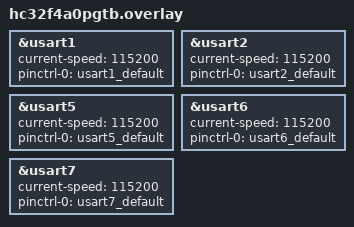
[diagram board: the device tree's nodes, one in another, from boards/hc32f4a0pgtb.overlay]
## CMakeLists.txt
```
# SPDX-License-Identifier: Apache-2.0

cmake_minimum_required(VERSION 3.20.0)

# Point Zephyr at the hc32f/ out-of-tree SoC + board tree (sibling directory).
set(HC32F_ROOT ${CMAKE_CURRENT_SOURCE_DIR}/../hc32f)
list(APPEND SOC_ROOT   ${HC32F_ROOT})
list(APPEND BOARD_ROOT ${HC32F_ROOT})
list(APPEND DTS_ROOT   ${HC32F_ROOT})

find_package(Zephyr REQUIRED HINTS $ENV{ZEPHYR_BASE})
project(fmr_cc)

target_include_directories(app PRIVATE src)

target_sources(app PRIVATE
	src/main.c
	src/app_msg.c
	src/crc16_modbus.c
	src/doraemon_pack.c
	src/led_statu.c
	src/wbus.c
	src/imu5115.c
	src/moto.c
	src/servo.c
	src/comm_485_lift.c
	src/manual_ctrl.c
	src/battery.c
	src/usb_uplink.c
)
```

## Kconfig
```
# SPDX-License-Identifier: Apache-2.0

mainmenu "FMR_CC application"

source "Kconfig.zephyr"

menu "FMR_CC business modules"

config APP_FMR_WBUS
	bool "WBUS/SBUS receiver (USART2)"
	default y

config APP_FMR_IMU
	bool "IMU-5115 parser (USART1)"
	default y

config APP_FMR_MOTO
	bool "Motor Modbus RTU (USART6 + RS485)"
	default y

config APP_FMR_SERVO
	bool "Feetech servo (USART7 + RS485)"
	default y

config APP_FMR_LIFT
	bool "Lift Modbus RTU (USART5 + RS485)"
	default y

config APP_FMR_MANUAL_CTRL
	bool "Manual control (WBUS->motor/servo/lift mapping)"
	default y

config APP_FMR_LED_595
	bool "74HC595 LED status bit-bang"
	default y

config APP_FMR_BATTERY
	bool "Battery ADC sampler"
	default n
	help
	  Requires an ADC driver for HC32F4A0 which is not yet implemented.

config APP_FMR_USB_UPLINK
	bool "USB CDC-ACM uplink"
	default n
	help
	  Requires an HC32F4A0 USB device controller driver which is not
	  yet implemented.  When disabled the uplink falls back to USART3
	  (the debug console).

endmenu
```

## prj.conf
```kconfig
# FMR_CC Zephyr port: base config
CONFIG_MAIN_STACK_SIZE=2048
CONFIG_SYSTEM_WORKQUEUE_STACK_SIZE=2048

CONFIG_GPIO=y
CONFIG_PINCTRL=y
CONFIG_SERIAL=y
CONFIG_UART_INTERRUPT_DRIVEN=y
CONFIG_CONSOLE=y
CONFIG_UART_CONSOLE=y

CONFIG_LOG=y
CONFIG_LOG_MODE_DEFERRED=y
CONFIG_LOG_DEFAULT_LEVEL=3
CONFIG_LOG_BUFFER_SIZE=2048

CONFIG_POLL=y
CONFIG_EVENTS=y
CONFIG_RING_BUFFER=y

# MPU off for bring-up
CONFIG_ARM_MPU=n
CONFIG_HW_STACK_PROTECTION=n
CONFIG_THREAD_NAME=y
CONFIG_THREAD_MONITOR=y

# Business module toggles
CONFIG_APP_FMR_WBUS=y
CONFIG_APP_FMR_IMU=y
CONFIG_APP_FMR_MOTO=y
CONFIG_APP_FMR_SERVO=y
CONFIG_APP_FMR_LIFT=y
CONFIG_APP_FMR_MANUAL_CTRL=y
CONFIG_APP_FMR_LED_595=y
# Battery/USB require ADC/USB drivers not yet ported; compile as stubs.
CONFIG_APP_FMR_BATTERY=n
CONFIG_APP_FMR_USB_UPLINK=n
```

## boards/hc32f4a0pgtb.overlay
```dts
/*
 * SPDX-License-Identifier: Apache-2.0
 *
 * FMR_CC application overlay for hc32f4a0pgtb board.
 * Enables USART1/2/5/6/7 with their pinctrl nodes defined in the board DTS.
 * USART3 is already enabled as the console in the board DTS.
 */

/* IMU5115 - USART1, 115200 8N1 */
&usart1 {
	current-speed = <115200>;
	pinctrl-0 = <&usart1_default>;
	pinctrl-names = "default";
	status = "okay";
};

/*
 * WBUS/SBUS receiver - USART2.
 * Wire protocol: 100000 baud, 8E2, signal-inverted (SBUS standard).
 * TODO: The HC32 UART driver does not yet expose CR1.SBS (start-bit sense
 * inversion), parity or 2-stop-bit DTS properties.  Set 115200 as a
 * placeholder; wbus.c manually patches the USART registers at runtime via
 * sys_write32() until the driver supports these properties.
 */
&usart2 {
	current-speed = <115200>; /* placeholder; wbus.c patches to 100000 + SBS */
	pinctrl-0 = <&usart2_default>;
	pinctrl-names = "default";
	status = "okay";
};

/* Lift RS485 - USART5, 115200 8N1 */
&usart5 {
	current-speed = <115200>;
	pinctrl-0 = <&usart5_default>;
	pinctrl-names = "default";
	status = "okay";
};

/* Motor RS485 - USART6, 115200 8N1 */
&usart6 {
	current-speed = <115200>;
	pinctrl-0 = <&usart6_default>;
	pinctrl-names = "default";
	status = "okay";
};

/* Servo RS485 - USART7, 115200 8N1 */
&usart7 {
	current-speed = <115200>;
	pinctrl-0 = <&usart7_default>;
	pinctrl-names = "default";
	status = "okay";
};
```

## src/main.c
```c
/*
 * SPDX-License-Identifier: Apache-2.0
 *
 * @file main.c
 * @brief FMR_CC main entry point — Zephyr RTOS port.
 *
 * Initialises all modules then returns (Zephyr keeps threads running).
 * Replaces the original bare-metal superloop in main.c.
 *
 * Periodic tasks previously handled by soft_timer.c are now implemented
 * with k_work_delayable inside each module.  The timers started here
 * match the original schedule:
 *   - Motor speed poll  : every 200 ms
 *   - Servo/lift poll   : every 1000 ms
 *   - Status upload     : every 200 ms (in usb_uplink.c)
 *   - IMU upload        : every 50 ms  (in usb_uplink.c)
 *   - Battery ADC       : every 10 s   (battery.c TODO)
 */

#include "app_msg.h"
#include "led_statu.h"
#include "wbus.h"
#include "imu5115.h"
#include "moto.h"
#include "servo.h"
#include "comm_485_lift.h"
#include "manual_ctrl.h"
#include "battery.h"
#include "usb_uplink.h"

#include <zephyr/kernel.h>
#include <zephyr/logging/log.h>

LOG_MODULE_REGISTER(main, LOG_LEVEL_INF);

/* Periodic work items for timed polling commands */
static struct k_work_delayable read_speed_work;
static struct k_work_delayable read_servo_lift_work;

static void read_speed_work_fn(struct k_work *w)
{
	moto_cmd_get_all_speed();
	k_work_reschedule((struct k_work_delayable *)w, K_MSEC(200));
}

static void read_servo_lift_work_fn(struct k_work *w)
{
	servo_cmd_get_all_pos();
	comm_485_1_cmd_get_lift_pos();
	k_work_reschedule((struct k_work_delayable *)w, K_MSEC(1000));
}

int main(void)
{
	printk("\n");
	printk("========================================\n");
	printk("  FMR_CC Zephyr Port — starting up      \n");
	printk("  Build: %s %s                           \n", __DATE__, __TIME__);
	printk("========================================\n");

	LOG_INF("Initialising modules...");

	/* Message bus first — everything else uses it */
	app_msg_init();

	/* LED status (optional) */
	if (led_statu_init() != 0) {
		LOG_WRN("led_statu init failed (non-fatal)");
	}

	/* RC receiver */
	if (wbus_init() != 0) {
		LOG_WRN("wbus init failed");
	}

	/* IMU */
	if (imu_init() != 0) {
		LOG_WRN("imu init failed");
	}

	/* Motor controller */
	if (moto_init() != 0) {
		LOG_WRN("moto init failed");
	}

	/* Servo controller */
	if (servo_init() != 0) {
		LOG_WRN("servo init failed");
	}

	/* Lift controller */
	if (comm_485_lift_init() != 0) {
		LOG_WRN("comm_485_lift init failed");
	}

	/* Manual control (RC → motor) */
	if (manual_ctrl_init() != 0) {
		LOG_WRN("manual_ctrl init failed");
	}

	/* Battery ADC (stub) */
	if (battery_init() != 0) {
		LOG_WRN("battery init failed");
	}

	/* USB / console uplink */
	if (usb_uplink_init() != 0) {
		LOG_WRN("usb_uplink init failed");
	}

	/* Start periodic polling work items */
	k_work_init_delayable(&read_speed_work, read_speed_work_fn);
	k_work_reschedule(&read_speed_work, K_MSEC(500)); /* initial delay */

	k_work_init_delayable(&read_servo_lift_work, read_servo_lift_work_fn);
	k_work_reschedule(&read_servo_lift_work, K_MSEC(1000));

	LOG_INF("All modules initialised — system running");

	/*
	 * Returning from main() is valid in Zephyr; the kernel continues to
	 * schedule threads.  No superloop needed.
	 */
	return 0;
}
```

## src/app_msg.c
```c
/*
 * SPDX-License-Identifier: Apache-2.0
 *
 * @file app_msg.c
 * @brief Application message bus implementation.
 *
 * Provides a simple publish/subscribe model on top of Zephyr k_msgq.
 * Replaces the bare-metal msg.c circular queue.
 */

#include "app_msg.h"
#include <zephyr/logging/log.h>
#include <string.h>

LOG_MODULE_REGISTER(app_msg, LOG_LEVEL_INF);

struct subscriber {
	struct k_msgq *q;
	uint32_t       type_mask;
};

static struct subscriber subscribers[APP_MSG_MAX_SUBSCRIBERS];
static int sub_count;

int app_msg_init(void)
{
	memset(subscribers, 0, sizeof(subscribers));
	sub_count = 0;
	LOG_INF("app_msg init");
	return 0;
}

int app_msg_subscribe(struct k_msgq *q, uint32_t type_mask)
{
	if (sub_count >= APP_MSG_MAX_SUBSCRIBERS) {
		LOG_ERR("subscriber table full");
		return -ENOMEM;
	}
	subscribers[sub_count].q         = q;
	subscribers[sub_count].type_mask = type_mask;
	sub_count++;
	return 0;
}

void app_msg_publish(const struct app_msg *msg)
{
	uint32_t bit = BIT(msg->type);

	for (int i = 0; i < sub_count; i++) {
		if (subscribers[i].type_mask & bit) {
			/* Non-blocking: drop if queue is full */
			int ret = k_msgq_put(subscribers[i].q, msg, K_NO_WAIT);
			if (ret) {
				LOG_WRN("msg type %d dropped (q full)", msg->type);
			}
		}
	}
}
```

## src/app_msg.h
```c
/*
 * SPDX-License-Identifier: Apache-2.0
 *
 * @file app_msg.h
 * @brief Application-wide inter-module message bus.
 *
 * Replaces the bare-metal msg.c circular queue.  Each module publishes typed
 * messages; subscribers register a k_msgq and receive copies via
 * app_msg_subscribe() / app_msg_publish().
 *
 * Usage:
 *   // Publisher (e.g. wbus.c):
 *   struct app_msg m = { .type = MSG_RC_FRAME, .rc = frame };
 *   app_msg_publish(&m);
 *
 *   // Subscriber (e.g. manual_ctrl.c):
 *   K_MSGQ_DEFINE(my_q, sizeof(struct app_msg), 8, 4);
 *   app_msg_subscribe(&my_q, BIT(MSG_RC_FRAME));
 *   struct app_msg m;
 *   k_msgq_get(&my_q, &m, K_FOREVER);
 */

#ifndef APP_MSG_H
#define APP_MSG_H

#include <stdint.h>
#include <zephyr/kernel.h>

#ifdef __cplusplus
extern "C" {
#endif

/** Message type identifiers */
enum app_msg_type {
	MSG_RC_FRAME = 0,   /**< WBUS/SBUS decoded channel data */
	MSG_IMU_FRAME,      /**< IMU5115 decoded frame */
	MSG_MOTO_STATUS,    /**< Motor speed feedback */
	MSG_SERVO_STATUS,   /**< Servo position feedback */
	MSG_LIFT_STATUS,    /**< Lift position feedback */
	MSG_BAT_VOLT,       /**< Battery voltage (mV) */
	MSG_MOTO_CMD,       /**< Motor speed command (from manual_ctrl) */
	MSG_SERVO_CMD,      /**< Servo position command */
	MSG_LIFT_CMD,       /**< Lift position command */
	MSG_TYPE_MAX
};

/** RC frame payload – decoded SBUS/WBUS channels */
struct app_msg_rc {
	int16_t ch[10];   /**< Channels 1-10, normalised ±100 */
	uint8_t  status;  /**< 0=normal, 1=no-signal, 2=no-device */
};

/** IMU frame payload */
struct app_msg_imu {
	uint32_t gx, gy, gz;
	uint32_t ax, ay, az;
	uint16_t frame_seq;
};

/** Motor status / command payload */
struct app_msg_moto {
	int16_t l_speed; /**< Left wheel speed (RPM*factor) */
	int16_t r_speed; /**< Right wheel speed */
};

/** Servo command/status payload */
struct app_msg_servo {
	uint8_t  id;       /**< Servo ID 1-3 */
	int16_t  pos;      /**< Target / current position */
	int16_t  speed;    /**< Speed limit (0=max) */
	uint16_t time_ms;  /**< Move time (ms) */
};

/** Lift command/status payload */
struct app_msg_lift {
	int32_t  pos;      /**< Target / current position (encoder counts) */
	uint8_t  cmd;      /**< 0=set_pos, 1=calibrate, 2=go_zero */
};

/** Battery voltage payload */
struct app_msg_bat {
	uint16_t voltage_mv; /**< Battery voltage in millivolts */
};

/** Application message container */
struct app_msg {
	enum app_msg_type type;
	union {
		struct app_msg_rc    rc;
		struct app_msg_imu   imu;
		struct app_msg_moto  moto;
		struct app_msg_servo servo;
		struct app_msg_lift  lift;
		struct app_msg_bat   bat;
	};
};

/** Maximum number of simultaneous subscribers */
#define APP_MSG_MAX_SUBSCRIBERS 8

/**
 * @brief Initialise the message bus.
 * @return 0 on success.
 */
int app_msg_init(void);

/**
 * @brief Subscribe a message queue to receive messages of the given types.
 *
 * @param q       Caller-owned k_msgq (must hold sizeof(struct app_msg) items).
 * @param type_mask Bitmask of (1 << enum app_msg_type) values to receive.
 * @return 0 on success, -ENOMEM if subscriber table is full.
 */
int app_msg_subscribe(struct k_msgq *q, uint32_t type_mask);

/**
 * @brief Publish a message to all subscribers interested in its type.
 *
 * May be called from any context (including ISR) — uses k_msgq_put with
 * K_NO_WAIT so it never blocks.
 *
 * @param msg Message to broadcast.
 */
void app_msg_publish(const struct app_msg *msg);

#ifdef __cplusplus
}
#endif

#endif /* APP_MSG_H */
```

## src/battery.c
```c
/*
 * SPDX-License-Identifier: Apache-2.0
 *
 * @file battery.c
 * @brief Battery voltage measurement stub.
 *
 * TODO: Implement ADC sampling using the Zephyr ADC API when a driver for
 * HC32F4A0 ADC1 (PA0, channel 0) becomes available.  Original bare-metal
 * implementation is in /mnt/d/embed/HC32/FMR_CC_SW/v1_2/src/battery.c.
 *
 * Original conversion formula:
 *   voltage_mv = adc_raw * 625 / 1024 * 11
 * where adc_raw is a 12-bit value averaged over 8 samples.
 */

#include "battery.h"
#include <zephyr/logging/log.h>

LOG_MODULE_REGISTER(battery, LOG_LEVEL_INF);

#ifdef CONFIG_APP_FMR_BATTERY

/*
 * TODO: ADC support.
 *
 * Steps to implement:
 * 1. Add &adc1 node to the overlay with zephyr,adc-dt-spec pointing to
 *    PA0 (channel 0) once the HC32 ADC driver exposes the DT API.
 * 2. Use ADC_DT_SPEC_GET() + adc_sequence_init_dt() to configure.
 * 3. Call adc_read() from a k_work_delayable every ~1 s.
 * 4. Apply: voltage_mv = raw * 625 / 1024 * 11
 * 5. Publish MSG_BAT_VOLT to app_msg.
 */

static volatile uint32_t adc_value;

int battery_init(void)
{
	/* TODO: configure HC32 ADC1 via Zephyr ADC API */
	LOG_WRN("battery ADC not yet implemented (TODO)");
	adc_value = 0;
	return 0;
}

uint32_t battery_get_adc_value(void)
{
	return adc_value;
}

#else /* !CONFIG_APP_FMR_BATTERY */

int battery_init(void)
{
	return 0;
}

uint32_t battery_get_adc_value(void)
{
	return 0;
}

#endif /* CONFIG_APP_FMR_BATTERY */
```

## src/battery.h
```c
/*
 * SPDX-License-Identifier: Apache-2.0
 *
 * @file battery.h
 * @brief Battery voltage measurement header.
 *
 * TODO: ADC support via Zephyr ADC API is not yet implemented.
 * Original hardware: PA0, ADC1 CH0, 12-bit, averaged 8×.
 * Conversion: adc_raw * 625 / 1024 * 11 (voltage divider ×11).
 * See /mnt/d/embed/HC32/FMR_CC_SW/v1_2/src/battery.c for the original.
 *
 * When CONFIG_APP_FMR_BATTERY is not set, a stub returning 0 is used.
 */

#ifndef BATTERY_H
#define BATTERY_H

#include <stdint.h>

#ifdef __cplusplus
extern "C" {
#endif

/**
 * @brief Initialise the battery ADC module.
 * @return 0 on success, or stub 0.
 */
int battery_init(void);

/**
 * @brief Get the last sampled battery voltage in millivolts.
 *
 * TODO: Not yet implemented; always returns 0 until the Zephyr ADC driver
 * for HC32F4A0 ADC1 is available.
 *
 * @return Battery voltage in mV, or 0 if not implemented.
 */
uint32_t battery_get_adc_value(void);

#ifdef __cplusplus
}
#endif

#endif /* BATTERY_H */
```

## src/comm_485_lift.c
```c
/*
 * SPDX-License-Identifier: Apache-2.0
 *
 * @file comm_485_lift.c
 * @brief Lift RS485 driver — Zephyr port of original comm_485_1.c.
 *
 * USART5 (PA11/PA8), 115200 8N1, RS485 half-duplex.
 * DE = lift_de (PA10, active-high), RE = lift_re (PA9, active-high).
 *
 * Frame format (custom, NOT Modbus):
 *   TX/RX: 0x39 0x93 | ID(1) | CMD(1) | LEN(1) | DATA(LEN) | CRC16_H | CRC16_L
 *   CRC16-Modbus covers bytes starting from ID through end of DATA.
 *
 * The RX state machine parses incoming frames using the same byte-level
 * sequence as the original _execute_rx_data() function.
 */

#include "comm_485_lift.h"

#ifdef CONFIG_APP_FMR_LIFT

#include "app_msg.h"
#include "crc16_modbus.h"
#include "doraemon_pack.h"

#include <zephyr/kernel.h>
#include <zephyr/device.h>
#include <zephyr/drivers/uart.h>
#include <zephyr/drivers/gpio.h>
#include <zephyr/logging/log.h>
#include <string.h>

LOG_MODULE_REGISTER(comm_485_lift, LOG_LEVEL_INF);

/* ---------------------------------------------------------------------------
 * Hardware resources
 * ---------------------------------------------------------------------------
 */
static const struct device *usart5_dev = DEVICE_DT_GET(DT_NODELABEL(usart5));

static const struct gpio_dt_spec de_gpio =
	GPIO_DT_SPEC_GET(DT_NODELABEL(lift_de), gpios);
static const struct gpio_dt_spec re_gpio =
	GPIO_DT_SPEC_GET(DT_NODELABEL(lift_re), gpios);

/* ---------------------------------------------------------------------------
 * Protocol constants (from original comm_485_1.h/.c)
 * ---------------------------------------------------------------------------
 */
#define LIFT_FRAME_HEAD1   0x39U
#define LIFT_FRAME_HEAD2   0x93U
#define LIFT_DEVICE_ID     0x01U

#define LIFT_CMD_SET_POS      0x03U
#define LIFT_CMD_GET_POS      0x05U
#define LIFT_CMD_CALIBRATE    0x07U
#define LIFT_CMD_GO_ZERO      0x08U
#define LIFT_CMD_GET_MAX      0x09U

#define LIFT_TASK_MAX      10
#define LIFT_TX_BUF_MAX    32
#define LIFT_RX_BUF_MAX    32
#define LIFT_TIMEOUT_MS    150
#define LIFT_RETRY_MAX     3

/* ---------------------------------------------------------------------------
 * RS485 direction
 * ---------------------------------------------------------------------------
 */
static inline void rs485_tx_mode(void)
{
	gpio_pin_set_dt(&de_gpio, 1);
	gpio_pin_set_dt(&re_gpio, 0);
}

static inline void rs485_rx_mode(void)
{
	gpio_pin_set_dt(&de_gpio, 0);
	gpio_pin_set_dt(&re_gpio, 1);
}

/* ---------------------------------------------------------------------------
 * RX ring buffer
 * ---------------------------------------------------------------------------
 */
#define RX_RING 128
static uint8_t rx_ring[RX_RING];
static uint32_t rx_head, rx_tail;
static struct k_spinlock rx_lock;
static K_SEM_DEFINE(rx_sem, 0, 1);

static void uart_cb(const struct device *dev, void *user_data)
{
	ARG_UNUSED(user_data);

	if (!uart_irq_update(dev)) {
		return;
	}

	bool got = false;

	while (uart_irq_rx_ready(dev)) {
		uint8_t c;

		if (uart_fifo_read(dev, &c, 1) != 1) {
			break;
		}
		k_spinlock_key_t key = k_spin_lock(&rx_lock);
		uint32_t next = (rx_tail + 1) % RX_RING;

		if (next != rx_head) {
			rx_ring[rx_tail] = c;
			rx_tail = next;
			got = true;
		}
		k_spin_unlock(&rx_lock, key);
	}
	if (got) {
		k_sem_give(&rx_sem);
	}
}

static int rx_drain(uint8_t *dst, int max)
{
	k_spinlock_key_t key = k_spin_lock(&rx_lock);
	int n = 0;

	while (rx_head != rx_tail && n < max) {
		dst[n++] = rx_ring[rx_head];
		rx_head  = (rx_head + 1) % RX_RING;
	}
	k_spin_unlock(&rx_lock, key);
	return n;
}

/* ---------------------------------------------------------------------------
 * Frame builder: 0x39 0x93 ID CMD LEN DATA... CRC_H CRC_L
 * CRC covers bytes from [ID] through [DATA end].
 * ---------------------------------------------------------------------------
 */
static int build_frame(uint8_t *out, uint8_t id, uint8_t cmd,
		       const uint8_t *data, uint8_t data_len)
{
	out[0] = LIFT_FRAME_HEAD1;
	out[1] = LIFT_FRAME_HEAD2;
	out[2] = id;
	out[3] = cmd;
	out[4] = data_len;
	if (data_len > 0) {
		memcpy(&out[5], data, data_len);
	}
	/* CRC over [id, cmd, len, data...] i.e. from out[2] */
	uint16_t crc = calc_modbus_crc16(&out[2], 3 + data_len);

	out[5 + data_len] = (uint8_t)(crc >> 8);
	out[6 + data_len] = (uint8_t)(crc & 0xff);
	return 7 + data_len;
}

/* ---------------------------------------------------------------------------
 * Lift state
 * ---------------------------------------------------------------------------
 */
static volatile uint32_t lift_pos;
static volatile uint32_t lift_calibrate;

/* ---------------------------------------------------------------------------
 * Task queue
 * ---------------------------------------------------------------------------
 */
typedef int8_t (*lift_handler_t)(const uint8_t *dat, uint16_t len);

struct lift_task {
	uint8_t  cmd_buf[LIFT_TX_BUF_MAX];
	uint8_t  cmd_len;
	uint8_t  rsp_cmd;    /**< expected response CMD byte (0=any/use handler) */
	lift_handler_t handler;
};

K_MSGQ_DEFINE(lift_task_q, sizeof(struct lift_task), LIFT_TASK_MAX, 4);

/* ---------------------------------------------------------------------------
 * RX frame parser (mirrors original _execute_rx_data byte-state machine)
 * Output: decoded [id, cmd, len, data...] into rq_buf, returns len or -1.
 * ---------------------------------------------------------------------------
 */
enum rs485_rx_state {
	RS485_RX_HEAD1 = 0,
	RS485_RX_HEAD2,
	RS485_RX_ID,
	RS485_RX_CMD,
	RS485_RX_LEN,
	RS485_RX_DATA,
	RS485_RX_CRCH,
	RS485_RX_CRCL,
};

static int parse_rx_frame(const uint8_t *src, int src_len,
			  uint8_t *out, uint16_t *out_len)
{
	static enum rs485_rx_state state = RS485_RX_HEAD1;
	static uint8_t rq[LIFT_RX_BUF_MAX];
	static uint16_t pkt_len, data_pos;
	static uint16_t crc;

	for (int i = 0; i < src_len; i++) {
		uint8_t b = src[i];

		switch (state) {
		case RS485_RX_HEAD1:
			if (b == LIFT_FRAME_HEAD1) {
				state = RS485_RX_HEAD2;
				data_pos = 0;
			}
			break;
		case RS485_RX_HEAD2:
			state = (b == LIFT_FRAME_HEAD2) ? RS485_RX_ID : RS485_RX_HEAD1;
			break;
		case RS485_RX_ID:
			rq[0] = b;
			state = RS485_RX_CMD;
			break;
		case RS485_RX_CMD:
			rq[1] = b;
			state = RS485_RX_LEN;
			break;
		case RS485_RX_LEN:
			rq[2]   = b;
			pkt_len = b;
			state   = (pkt_len == 0) ? RS485_RX_CRCH : RS485_RX_DATA;
			break;
		case RS485_RX_DATA:
			rq[3 + data_pos] = b;
			data_pos++;
			if (data_pos >= pkt_len) {
				state = RS485_RX_CRCH;
			}
			break;
		case RS485_RX_CRCH:
			crc   = (uint16_t)b << 8;
			state = RS485_RX_CRCL;
			break;
		case RS485_RX_CRCL:
			crc |= b;
			state = RS485_RX_HEAD1;
			if (calc_modbus_crc16(rq, pkt_len + 3) == crc) {
				memcpy(out, rq, pkt_len + 3);
				*out_len = pkt_len + 3;
				return 1;
			}
			LOG_WRN("lift: CRC error");
			return -1;
		}
	}
	return 0; /* incomplete */
}

/* ---------------------------------------------------------------------------
 * Response handlers
 * ---------------------------------------------------------------------------
 */
static int8_t get_pos_handler(const uint8_t *p, uint16_t len)
{
	if (len < 7) {
		return 1;
	}
	/* p[0]=id, p[1]=cmd(0x85), p[2]=len(4), p[3..6]=pos big-endian */
	lift_pos = ((uint32_t)p[3] << 24) | ((uint32_t)p[4] << 16) |
		   ((uint32_t)p[5] << 8) | p[6];

	struct app_msg msg = {
		.type     = MSG_LIFT_STATUS,
		.lift.pos = (int32_t)lift_pos,
	};
	app_msg_publish(&msg);
	return 0;
}

static int8_t get_max_handler(const uint8_t *p, uint16_t len)
{
	if (len < 7) {
		return 1;
	}
	lift_calibrate = ((uint32_t)p[3] << 24) | ((uint32_t)p[4] << 16) |
			 ((uint32_t)p[5] << 8) | p[6];
	return 0;
}

/* ---------------------------------------------------------------------------
 * Lift thread
 * ---------------------------------------------------------------------------
 */
#define LIFT_STACK_SIZE 1024
K_THREAD_STACK_DEFINE(lift_stack, LIFT_STACK_SIZE);
static struct k_thread lift_thread_data;

static void lift_thread_fn(void *a, void *b, void *c)
{
	ARG_UNUSED(a); ARG_UNUSED(b); ARG_UNUSED(c);

	struct lift_task task;
	uint8_t rx_raw[LIFT_RX_BUF_MAX];
	uint8_t rx_frame[LIFT_RX_BUF_MAX];

	while (1) {
		k_msgq_get(&lift_task_q, &task, K_FOREVER);

		int retry = 0;

		do {
			rx_drain(rx_raw, sizeof(rx_raw)); /* flush stale */

			rs485_tx_mode();
			uart_tx(usart5_dev, task.cmd_buf, task.cmd_len, SYS_FOREVER_US);
			k_msleep(2);
			rs485_rx_mode();

			int64_t deadline = k_uptime_get() + LIFT_TIMEOUT_MS;
			int rx_len = 0;

			while (k_uptime_get() < deadline) {
				int r = k_sem_take(&rx_sem, K_MSEC(10));

				if (r == 0) {
					rx_len += rx_drain(&rx_raw[rx_len],
							   sizeof(rx_raw) - rx_len);
				}
			}

			if (rx_len == 0) {
				LOG_WRN("lift: no response (retry %d)", retry);
				retry++;
				continue;
			}

			uint16_t frame_len = 0;
			int pr = parse_rx_frame(rx_raw, rx_len, rx_frame, &frame_len);

			if (pr <= 0) {
				LOG_WRN("lift: parse error %d (retry %d)", pr, retry);
				retry++;
				continue;
			}

			int ok;

			if (task.handler) {
				ok = (task.handler(rx_frame, frame_len) == 0);
			} else {
				/* Expect response CMD = request CMD | 0x80 */
				ok = (rx_frame[1] == (task.rsp_cmd | 0x80));
			}

			if (ok) {
				break;
			}
			retry++;
		} while (retry < LIFT_RETRY_MAX);

		if (retry >= LIFT_RETRY_MAX) {
			LOG_ERR("lift: task failed after %d retries", LIFT_RETRY_MAX);
		}
	}
}

/* ---------------------------------------------------------------------------
 * Public API
 * ---------------------------------------------------------------------------
 */
int comm_485_lift_init(void)
{
	int ret;

	if (!device_is_ready(usart5_dev)) {
		LOG_ERR("USART5 not ready");
		return -ENODEV;
	}
	ret = gpio_pin_configure_dt(&de_gpio, GPIO_OUTPUT_INACTIVE);
	if (ret) {
		return ret;
	}
	ret = gpio_pin_configure_dt(&re_gpio, GPIO_OUTPUT_INACTIVE);
	if (ret) {
		return ret;
	}
	rs485_rx_mode();

	uart_irq_callback_user_data_set(usart5_dev, uart_cb, NULL);
	uart_irq_rx_enable(usart5_dev);

	k_thread_create(&lift_thread_data, lift_stack, LIFT_STACK_SIZE,
			lift_thread_fn, NULL, NULL, NULL,
			K_PRIO_COOP(7), 0, K_NO_WAIT);
	k_thread_name_set(&lift_thread_data, "lift");

	LOG_INF("comm_485_lift init OK (USART5)");
	return 0;
}

void comm_485_1_cmd_set_lift_pos(int32_t pos)
{
	uint8_t dat[4];

	dat[0] = (uint8_t)((pos >> 24) & 0xff);
	dat[1] = (uint8_t)((pos >> 16) & 0xff);
	dat[2] = (uint8_t)((pos >> 8)  & 0xff);
	dat[3] = (uint8_t)(pos & 0xff);

	struct lift_task task = {0};

	task.cmd_len = build_frame(task.cmd_buf, LIFT_DEVICE_ID,
				   LIFT_CMD_SET_POS, dat, 4);
	task.rsp_cmd = LIFT_CMD_SET_POS;
	task.handler = NULL;
	k_msgq_put(&lift_task_q, &task, K_NO_WAIT);
}

void comm_485_1_cmd_get_lift_pos(void)
{
	struct lift_task task = {0};

	task.cmd_len = build_frame(task.cmd_buf, LIFT_DEVICE_ID,
				   LIFT_CMD_GET_POS, NULL, 0);
	task.rsp_cmd = 0;
	task.handler = get_pos_handler;
	k_msgq_put(&lift_task_q, &task, K_NO_WAIT);
}

void comm_485_1_cmd_calibrate(void)
{
	struct lift_task task = {0};

	task.cmd_len = build_frame(task.cmd_buf, LIFT_DEVICE_ID,
				   LIFT_CMD_CALIBRATE, NULL, 0);
	task.rsp_cmd = LIFT_CMD_CALIBRATE;
	task.handler = NULL;
	k_msgq_put(&lift_task_q, &task, K_NO_WAIT);
}

void comm_485_1_cmd_go_zero(void)
{
	struct lift_task task = {0};

	task.cmd_len = build_frame(task.cmd_buf, LIFT_DEVICE_ID,
				   LIFT_CMD_GO_ZERO, NULL, 0);
	task.rsp_cmd = LIFT_CMD_GO_ZERO;
	task.handler = NULL;
	k_msgq_put(&lift_task_q, &task, K_NO_WAIT);
}

void comm_485_1_cmd_get_lift_max(void)
{
	struct lift_task task = {0};

	task.cmd_len = build_frame(task.cmd_buf, LIFT_DEVICE_ID,
				   LIFT_CMD_GET_MAX, NULL, 0);
	task.rsp_cmd = 0;
	task.handler = get_max_handler;
	k_msgq_put(&lift_task_q, &task, K_NO_WAIT);
}

uint32_t comm_485_1_get_lift_pos(void)
{
	return lift_pos;
}

uint32_t comm_485_1_get_lift_calibrate_value(void)
{
	return lift_calibrate;
}

#else /* !CONFIG_APP_FMR_LIFT */

int      comm_485_lift_init(void)              { return 0; }
void     comm_485_1_cmd_set_lift_pos(int32_t p) { (void)p; }
void     comm_485_1_cmd_get_lift_pos(void)     {}
void     comm_485_1_cmd_calibrate(void)        {}
void     comm_485_1_cmd_go_zero(void)          {}
void     comm_485_1_cmd_get_lift_max(void)     {}
uint32_t comm_485_1_get_lift_pos(void)         { return 0; }
uint32_t comm_485_1_get_lift_calibrate_value(void) { return 0; }

#endif /* CONFIG_APP_FMR_LIFT */
```

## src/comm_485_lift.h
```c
/*
 * SPDX-License-Identifier: Apache-2.0
 *
 * @file comm_485_lift.h
 * @brief Lift controller RS485 driver header.
 *
 * USART5, 115200 bps, 8N1, RS485 half-duplex.
 * DE=PA10 (active-high), RE=PA9 (active-high in Zephyr, active-low on wire).
 * Device ID: 0x01.
 *
 * Custom frame format (from original comm_485_1.c):
 *   TX: 0x39 0x93 | ID(1) | CMD(1) | LEN(1) | DATA(LEN) | CRC_H | CRC_L
 *   RX: same layout; CRC16-Modbus covers bytes [ID..DATA_end]
 *
 * Supported commands:
 *   0x03  set position (DATA=int32 big-endian, response CMD=0x83)
 *   0x05  read position (response 4 bytes)
 *   0x07  calibrate zero (response CMD=0x87)
 *   0x08  go to zero (response CMD=0x88)
 *   0x09  read max travel (response 4 bytes)
 */

#ifndef COMM_485_LIFT_H
#define COMM_485_LIFT_H

#include <stdint.h>

#ifdef __cplusplus
extern "C" {
#endif

/**
 * @brief Initialise the lift RS485 driver (USART5 + thread).
 * @return 0 on success.
 */
int comm_485_lift_init(void);

/** @brief Enqueue a set-position command. */
void comm_485_1_cmd_set_lift_pos(int32_t pos);

/** @brief Enqueue a read-position query. */
void comm_485_1_cmd_get_lift_pos(void);

/** @brief Enqueue a zero-calibration command. */
void comm_485_1_cmd_calibrate(void);

/** @brief Enqueue a go-to-zero command. */
void comm_485_1_cmd_go_zero(void);

/** @brief Enqueue a read-max-travel query. */
void comm_485_1_cmd_get_lift_max(void);

/** @brief Get the last received lift position. */
uint32_t comm_485_1_get_lift_pos(void);

/** @brief Get the last received max-travel value. */
uint32_t comm_485_1_get_lift_calibrate_value(void);

#ifdef __cplusplus
}
#endif

#endif /* COMM_485_LIFT_H */
```

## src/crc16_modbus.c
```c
/*
 * SPDX-License-Identifier: Apache-2.0
 *
 * @file crc16_modbus.c
 * @brief Modbus CRC16 table-lookup — straight copy of original bare-metal code.
 *
 * No changes from /mnt/d/embed/HC32/FMR_CC_SW/v1_2/src/crc16_modbus.c;
 * wire behaviour is identical.
 */

#include "crc16_modbus.h"
#include <zephyr/logging/log.h>

LOG_MODULE_REGISTER(crc16_modbus, LOG_LEVEL_INF);

unsigned short calc_modbus_crc16(const unsigned char *p, int n)
{
	static const unsigned short crc_table[] = {
		0x0000, 0xC0C1, 0xC181, 0x0140, 0xC301, 0x03C0, 0x0280, 0xC241,
		0xC601, 0x06C0, 0x0780, 0xC741, 0x0500, 0xC5C1, 0xC481, 0x0440,
		0xCC01, 0x0CC0, 0x0D80, 0xCD41, 0x0F00, 0xCFC1, 0xCE81, 0x0E40,
		0x0A00, 0xCAC1, 0xCB81, 0x0B40, 0xC901, 0x09C0, 0x0880, 0xC841,
		0xD801, 0x18C0, 0x1980, 0xD941, 0x1B00, 0xDBC1, 0xDA81, 0x1A40,
		0x1E00, 0xDEC1, 0xDF81, 0x1F40, 0xDD01, 0x1DC0, 0x1C80, 0xDC41,
		0x1400, 0xD4C1, 0xD581, 0x1540, 0xD701, 0x17C0, 0x1680, 0xD641,
		0xD201, 0x12C0, 0x1380, 0xD341, 0x1100, 0xD1C1, 0xD081, 0x1040,
		0xF001, 0x30C0, 0x3180, 0xF141, 0x3300, 0xF3C1, 0xF281, 0x3240,
		0x3600, 0xF6C1, 0xF781, 0x3740, 0xF501, 0x35C0, 0x3480, 0xF441,
		0x3C00, 0xFCC1, 0xFD81, 0x3D40, 0xFF01, 0x3FC0, 0x3E80, 0xFE41,
		0xFA01, 0x3AC0, 0x3B80, 0xFB41, 0x3900, 0xF9C1, 0xF881, 0x3840,
		0x2800, 0xE8C1, 0xE981, 0x2940, 0xEB01, 0x2BC0, 0x2A80, 0xEA41,
		0xEE01, 0x2EC0, 0x2F80, 0xEF41, 0x2D00, 0xEDC1, 0xEC81, 0x2C40,
		0xE401, 0x24C0, 0x2580, 0xE541, 0x2700, 0xE7C1, 0xE681, 0x2640,
		0x2200, 0xE2C1, 0xE381, 0x2340, 0xE101, 0x21C0, 0x2080, 0xE041,
		0xA001, 0x60C0, 0x6180, 0xA141, 0x6300, 0xA3C1, 0xA281, 0x6240,
		0x6600, 0xA6C1, 0xA781, 0x6740, 0xA501, 0x65C0, 0x6480, 0xA441,
		0x6C00, 0xACC1, 0xAD81, 0x6D40, 0xAF01, 0x6FC0, 0x6E80, 0xAE41,
		0xAA01, 0x6AC0, 0x6B80, 0xAB41, 0x6900, 0xA9C1, 0xA881, 0x6840,
		0x7800, 0xB8C1, 0xB981, 0x7940, 0xBB01, 0x7BC0, 0x7A80, 0xBA41,
		0xBE01, 0x7EC0, 0x7F80, 0xBF41, 0x7D00, 0xBDC1, 0xBC81, 0x7C40,
		0xB401, 0x74C0, 0x7580, 0xB541, 0x7700, 0xB7C1, 0xB681, 0x7640,
		0x7200, 0xB2C1, 0xB381, 0x7340, 0xB101, 0x71C0, 0x7080, 0xB041,
		0x5000, 0x90C1, 0x9181, 0x5140, 0x9301, 0x53C0, 0x5280, 0x9241,
		0x9601, 0x56C0, 0x5780, 0x9741, 0x5500, 0x95C1, 0x9481, 0x5440,
		0x9C01, 0x5CC0, 0x5D80, 0x9D41, 0x5F00, 0x9FC1, 0x9E81, 0x5E40,
		0x5A00, 0x9AC1, 0x9B81, 0x5B40, 0x9901, 0x59C0, 0x5880, 0x9841,
		0x8801, 0x48C0, 0x4980, 0x8941, 0x4B00, 0x8BC1, 0x8A81, 0x4A40,
		0x4E00, 0x8EC1, 0x8F81, 0x4F40, 0x8D01, 0x4DC0, 0x4C80, 0x8C41,
		0x4400, 0x84C1, 0x8581, 0x4540, 0x8701, 0x47C0, 0x4680, 0x8641,
		0x8201, 0x42C0, 0x4380, 0x8341, 0x4100, 0x81C1, 0x8081, 0x4040
	};

	unsigned char t;
	unsigned short crc = 0xFFFF;

	while (n--) {
		t = *p++ ^ crc;
		crc >>= 8;
		crc ^= crc_table[t];
	}

	return crc;
}
```

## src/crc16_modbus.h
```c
/*
 * SPDX-License-Identifier: Apache-2.0
 *
 * @file crc16_modbus.h
 * @brief Modbus CRC16 (table-lookup) — straight port of original crc16_modbus.c.
 */

#ifndef CRC16_MODBUS_H
#define CRC16_MODBUS_H

#include <stdint.h>

#ifdef __cplusplus
extern "C" {
#endif

/**
 * @brief Compute Modbus CRC16 over a byte array.
 *
 * Uses the standard Modbus polynomial 0x8005 (reflected).  Identical to the
 * original bare-metal implementation — wire-compatible with all RS485 slaves.
 *
 * @param p Pointer to data.
 * @param n Number of bytes.
 * @return CRC16 value (little-endian: low byte sent first on wire).
 */
unsigned short calc_modbus_crc16(const unsigned char *p, int n);

#ifdef __cplusplus
}
#endif

#endif /* CRC16_MODBUS_H */
```

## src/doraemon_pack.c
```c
/*
 * SPDX-License-Identifier: Apache-2.0
 *
 * @file doraemon_pack.c
 * @brief Byte-order conversion helpers — straight port of original doraemon_pack.c.
 */

#include "doraemon_pack.h"
#include <zephyr/logging/log.h>

LOG_MODULE_REGISTER(doraemon_pack, LOG_LEVEL_INF);

union u64u8_u {
	uint64_t n;
	uint8_t  a[8];
};

union u32u8_u {
	uint32_t n;
	uint8_t  a[4];
};

union u16u8_u {
	uint16_t n;
	uint8_t  a[2];
};

uint64_t dp_u8_2_u64_lsb(uint8_t *dat)
{
	union u64u8_u tmp;

	tmp.a[0] = dat[0]; tmp.a[1] = dat[1];
	tmp.a[2] = dat[2]; tmp.a[3] = dat[3];
	tmp.a[4] = dat[4]; tmp.a[5] = dat[5];
	tmp.a[6] = dat[6]; tmp.a[7] = dat[7];
	return tmp.n;
}

uint64_t dp_u8_2_u64_msb(uint8_t *dat)
{
	union u64u8_u tmp;

	tmp.a[0] = dat[7]; tmp.a[1] = dat[6];
	tmp.a[2] = dat[5]; tmp.a[3] = dat[4];
	tmp.a[4] = dat[3]; tmp.a[5] = dat[2];
	tmp.a[6] = dat[1]; tmp.a[7] = dat[0];
	return tmp.n;
}

int64_t dp_u8_2_i64_lsb(uint8_t *dat)
{
	uint64_t a = dp_u8_2_u64_lsb(dat);
	return *((int64_t *)(&a));
}

int64_t dp_u8_2_i64_msb(uint8_t *dat)
{
	uint64_t a = dp_u8_2_u64_msb(dat);
	return *((int64_t *)(&a));
}

uint32_t dp_u8_2_u32_lsb(uint8_t *dat)
{
	union u32u8_u tmp;

	tmp.a[0] = dat[0]; tmp.a[1] = dat[1];
	tmp.a[2] = dat[2]; tmp.a[3] = dat[3];
	return tmp.n;
}

uint32_t dp_u8_2_u32_msb(uint8_t *dat)
{
	union u32u8_u tmp;

	tmp.a[0] = dat[3]; tmp.a[1] = dat[2];
	tmp.a[2] = dat[1]; tmp.a[3] = dat[0];
	return tmp.n;
}

int32_t dp_u8_2_i32_lsb(uint8_t *dat)
{
	uint32_t a = dp_u8_2_u32_lsb(dat);
	return *((int32_t *)(&a));
}

int32_t dp_u8_2_i32_msb(uint8_t *dat)
{
	uint32_t a = dp_u8_2_u32_msb(dat);
	return *((int32_t *)(&a));
}

uint16_t dp_u8_2_u16_lsb(uint8_t *dat)
{
	union u16u8_u tmp;

	tmp.a[0] = dat[0]; tmp.a[1] = dat[1];
	return tmp.n;
}

uint16_t dp_u8_2_u16_msb(uint8_t *dat)
{
	union u16u8_u tmp;

	tmp.a[0] = dat[1]; tmp.a[1] = dat[0];
	return tmp.n;
}

int16_t dp_u8_2_i16_lsb(uint8_t *dat)
{
	uint16_t b = dp_u8_2_u16_lsb(dat);
	return *((int16_t *)(&b));
}

int16_t dp_u8_2_i16_msb(uint8_t *dat)
{
	uint16_t b = dp_u8_2_u16_msb(dat);
	return *((int16_t *)(&b));
}
```

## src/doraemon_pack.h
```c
/*
 * SPDX-License-Identifier: Apache-2.0
 *
 * @file doraemon_pack.h
 * @brief Byte-order conversion helpers — straight port of original doraemon_pack.
 *
 * Provides pack/unpack helpers for converting between byte arrays and
 * multi-byte integers in either LSB-first (little-endian) or MSB-first
 * (big-endian) order.  All functions are wire-compatible with the original.
 */

#ifndef DORAEMON_PACK_H
#define DORAEMON_PACK_H

#include <stdint.h>

#ifdef __cplusplus
extern "C" {
#endif

/* ---- Unpack: byte array → integer ---- */

uint64_t dp_u8_2_u64_lsb(uint8_t *dat);
uint64_t dp_u8_2_u64_msb(uint8_t *dat);
int64_t  dp_u8_2_i64_lsb(uint8_t *dat);
int64_t  dp_u8_2_i64_msb(uint8_t *dat);

uint32_t dp_u8_2_u32_lsb(uint8_t *dat);
uint32_t dp_u8_2_u32_msb(uint8_t *dat);
int32_t  dp_u8_2_i32_lsb(uint8_t *dat);
int32_t  dp_u8_2_i32_msb(uint8_t *dat);

uint16_t dp_u8_2_u16_lsb(uint8_t *dat);
uint16_t dp_u8_2_u16_msb(uint8_t *dat);
int16_t  dp_u8_2_i16_lsb(uint8_t *dat);
int16_t  dp_u8_2_i16_msb(uint8_t *dat);

/* ---- Helper macros (matching original doraemon_pack.h style) ---- */

/** Extract high byte of a uint16 */
#define DP_UINT16_H(x)  ((uint8_t)(((x) >> 8) & 0xff))
/** Extract low byte of a uint16 */
#define DP_UINT16_L(x)  ((uint8_t)((x) & 0xff))

/** Extract lower 32 bits of a 64-bit value (for printk formatting) */
#define DP_GET_U32(x)   ((uint32_t)((x) & 0xffffffff))

#ifdef __cplusplus
}
#endif

#endif /* DORAEMON_PACK_H */
```

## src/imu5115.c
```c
/*
 * SPDX-License-Identifier: Apache-2.0
 *
 * @file imu5115.c
 * @brief IMU5115 parser — Zephyr port of original imu5115.c.
 *
 * USART1, 115200 8N1.  IRQ-driven byte collector feeds a state machine
 * that assembles 34-byte frames (0xBD 0xDB 0x0A header) and validates the
 * trailing XOR checksum.  On success the decoded imu_dat_t is updated and
 * a MSG_IMU_FRAME message is published.
 */

#include "imu5115.h"
#include "app_msg.h"
#include "doraemon_pack.h"

#include <zephyr/kernel.h>
#include <zephyr/device.h>
#include <zephyr/drivers/uart.h>
#include <zephyr/logging/log.h>
#include <string.h>

LOG_MODULE_REGISTER(imu5115, LOG_LEVEL_INF);

#define IMU_FRAME_LEN   34
#define IMU_HEAD1       0xBDU
#define IMU_HEAD2       0xDBU
#define IMU_HEAD3       0x0AU

enum imu_rx_state {
	IMU_ST_HEAD1 = 0,
	IMU_ST_HEAD2,
	IMU_ST_HEAD3,
	IMU_ST_DATA,
	IMU_ST_CRC,
};

/* Ring buffer for raw bytes from ISR */
#define RX_BUF 256
static uint8_t rx_ring[RX_BUF];
static uint32_t rx_head, rx_tail;
static struct k_spinlock rx_lock;

static volatile imu_dat_t imu_dat;
static struct k_work parse_work;

static const struct device *usart1_dev = DEVICE_DT_GET(DT_NODELABEL(usart1));

static uint8_t xor_sum(const uint8_t *dat, uint32_t len)
{
	uint8_t s = 0;

	while (len--) {
		s ^= *dat++;
	}
	return s;
}

static void uart_cb(const struct device *dev, void *user_data)
{
	ARG_UNUSED(user_data);

	if (!uart_irq_update(dev)) {
		return;
	}

	while (uart_irq_rx_ready(dev)) {
		uint8_t c;

		if (uart_fifo_read(dev, &c, 1) != 1) {
			break;
		}
		k_spinlock_key_t key = k_spin_lock(&rx_lock);
		uint32_t next = (rx_tail + 1) % RX_BUF;

		if (next != rx_head) {
			rx_ring[rx_tail] = c;
			rx_tail = next;
		}
		k_spin_unlock(&rx_lock, key);
	}
	k_work_submit(&parse_work);
}

static void parse_work_fn(struct k_work *work)
{
	ARG_UNUSED(work);

	static enum imu_rx_state state = IMU_ST_HEAD1;
	static uint8_t  dat[IMU_FRAME_LEN];
	static uint8_t  rx_dat_len;

	k_spinlock_key_t key;
	uint8_t byte;

	while (true) {
		key = k_spin_lock(&rx_lock);
		if (rx_head == rx_tail) {
			k_spin_unlock(&rx_lock, key);
			break;
		}
		byte = rx_ring[rx_head];
		rx_head = (rx_head + 1) % RX_BUF;
		k_spin_unlock(&rx_lock, key);

		switch (state) {
		case IMU_ST_HEAD1:
			if (byte == IMU_HEAD1) {
				dat[0] = byte;
				state  = IMU_ST_HEAD2;
			}
			break;

		case IMU_ST_HEAD2:
			if (byte == IMU_HEAD2) {
				dat[1] = byte;
				state  = IMU_ST_HEAD3;
			} else {
				state = IMU_ST_HEAD1;
			}
			break;

		case IMU_ST_HEAD3:
			if (byte == IMU_HEAD3) {
				dat[2]     = byte;
				rx_dat_len = 3;
				state      = IMU_ST_DATA;
			} else {
				state = IMU_ST_HEAD1;
			}
			break;

		case IMU_ST_DATA:
			dat[rx_dat_len++] = byte;
			if (rx_dat_len >= IMU_FRAME_LEN - 1) {
				state = IMU_ST_CRC;
			}
			break;

		case IMU_ST_CRC:
			dat[rx_dat_len] = byte;
			if (xor_sum(dat, 33) == dat[33]) {
				imu_dat_t tmp;

				tmp.gx        = dp_u8_2_u32_lsb(&dat[3]);
				tmp.gy        = dp_u8_2_u32_lsb(&dat[7]);
				tmp.gz        = dp_u8_2_u32_lsb(&dat[11]);
				tmp.ax        = dp_u8_2_u32_lsb(&dat[15]);
				tmp.ay        = dp_u8_2_u32_lsb(&dat[19]);
				tmp.az        = dp_u8_2_u32_lsb(&dat[23]);
				tmp.frame_seq = dp_u8_2_u16_lsb(&dat[31]);
				tmp.tstamp    = k_uptime_get();

				memcpy((void *)&imu_dat, &tmp, sizeof(tmp));

				struct app_msg msg = {
					.type = MSG_IMU_FRAME,
					.imu  = {
						.gx        = tmp.gx,
						.gy        = tmp.gy,
						.gz        = tmp.gz,
						.ax        = tmp.ax,
						.ay        = tmp.ay,
						.az        = tmp.az,
						.frame_seq = tmp.frame_seq,
					},
				};
				app_msg_publish(&msg);
			} else {
				LOG_WRN("IMU XOR error");
			}
			rx_dat_len = 0;
			state = IMU_ST_HEAD1;
			break;
		}
	}
}

int imu_init(void)
{
	if (!device_is_ready(usart1_dev)) {
		LOG_ERR("USART1 not ready");
		return -ENODEV;
	}

	k_work_init(&parse_work, parse_work_fn);
	uart_irq_callback_user_data_set(usart1_dev, uart_cb, NULL);
	uart_irq_rx_enable(usart1_dev);

	LOG_INF("imu5115 init OK (USART1)");
	return 0;
}

void imu_get_dat(imu_dat_t *dat)
{
	memcpy(dat, (const void *)&imu_dat, sizeof(*dat));
}
```

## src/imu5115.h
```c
/*
 * SPDX-License-Identifier: Apache-2.0
 *
 * @file imu5115.h
 * @brief IMU5115 inertial measurement unit driver header.
 *
 * USART1, 115200 bps, 8N1, receive-only.
 * Frame: 0xBD 0xDB 0x0A + 24 bytes data + 2-byte seq + 1-byte XOR CRC = 34 bytes.
 * Publishes MSG_IMU_FRAME to app_msg bus on each valid frame.
 */

#ifndef IMU5115_H
#define IMU5115_H

#include <stdint.h>

#ifdef __cplusplus
extern "C" {
#endif

/** Decoded IMU data */
typedef struct {
	uint32_t gx, gy, gz;      /**< Angular velocity (raw) */
	uint32_t ax, ay, az;      /**< Linear acceleration (raw) */
	uint16_t frame_seq;       /**< Frame sequence counter */
	int64_t  tstamp;          /**< k_uptime_get() at reception */
} imu_dat_t;

/**
 * @brief Initialise the IMU5115 receiver (USART1).
 * @return 0 on success.
 */
int imu_init(void);

/**
 * @brief Copy the latest IMU data into the caller's buffer.
 * @param dat Output buffer.
 */
void imu_get_dat(imu_dat_t *dat);

#ifdef __cplusplus
}
#endif

#endif /* IMU5115_H */
```
